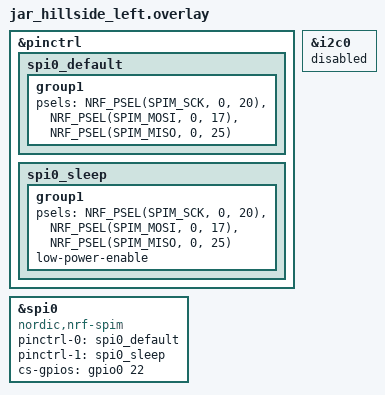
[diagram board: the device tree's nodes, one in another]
// Linke Haelfte (Central) - Matrix + nice!view.
// Das Display-Geraet (ls0xx) und das Status-Widget liefert das mitgebaute
// nice_view-Shield; hier wird nur der SPI-Bus mit deinen Pins definiert.
// Build: shield = "jar_hillside_left nice_view"

#include "jar_hillside.dtsi"

&pinctrl {
    spi0_default: spi0_default {
        group1 {
            psels = <NRF_PSEL(SPIM_SCK, 0, 20)>,    // SCK  P0.20
                <NRF_PSEL(SPIM_MOSI, 0, 17)>,       // MOSI P0.17
                <NRF_PSEL(SPIM_MISO, 0, 25)>;       // MISO (nicht verdrahtet, Pin reserviert)
        };
    };

    spi0_sleep: spi0_sleep {
        group1 {
            psels = <NRF_PSEL(SPIM_SCK, 0, 20)>,
                <NRF_PSEL(SPIM_MOSI, 0, 17)>,
                <NRF_PSEL(SPIM_MISO, 0, 25)>;
            low-power-enable;
        };
    };
};

nice_view_spi: &spi0 {
    status = "okay";
    compatible = "nordic,nrf-spim";
    pinctrl-0 = <&spi0_default>;
    pinctrl-1 = <&spi0_sleep>;
    pinctrl-names = "default", "sleep";
    cs-gpios = <&gpio0 22 GPIO_ACTIVE_HIGH>;        // CS  P0.22
};

// i2c0 belegt per Board-Default P0.17/P0.20 (kollidiert mit SPI oben) -> aus lassen.
&i2c0 {
    status = "disabled";
};
